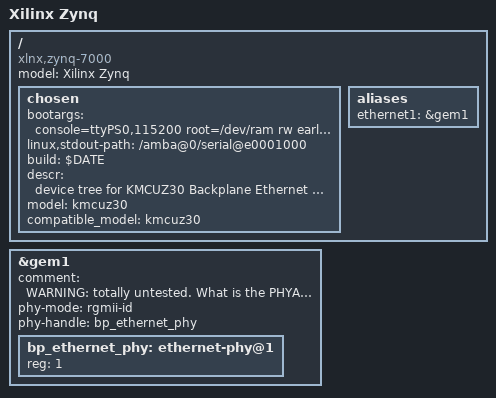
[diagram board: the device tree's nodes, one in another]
/*
* Copyright (C) 2013-2019 D-TACQ Solutions Ltd - http://www.d-tacq.com/
*
* This program is free software; you can redistribute it and/or modify
* it under the terms of the GNU General Public License version 2 as
* published by the Free Software Foundation.
*/

/dts-v1/;

#include "kmcu_common.dtsi"

/ {
       compatible = "xlnx,zynq-7000";
       model = "Xilinx Zynq";

       chosen {
	       bootargs = "console=ttyPS0,115200 root=/dev/ram rw earlyprintk";
	       linux,stdout-path = "/amba@0/serial@e0001000";
	       build="$DATE";	
	       descr="device tree for KMCUZ30 Backplane Ethernet - AMC with Z7030, TWO ELF SITES, adds MGT482 comms module, SPI";
	       model="kmcuz30";
	       compatible_model="kmcuz30";				
       };
	aliases {
		ethernet1 = &gem1;
	};
};

&gem1 {
	comment = "WARNING: totally untested. What is the PHYADDR. Is it the same phy after all?";
	status = "okay";
	phy-mode = "rgmii-id"; 
	/*
	phy-mode = "sgmii";	
	phy-reset-gpio = <&gpio0 47 0>;
	phy-reset-active-low = <1>;
	phy-reset-duration = <1>;
	*/
	phy-handle = <&bp_ethernet_phy>;
	bp_ethernet_phy: ethernet-phy@1 {
		reg = <1>;
		device_type = "ethernet-phy";
	};	
};

